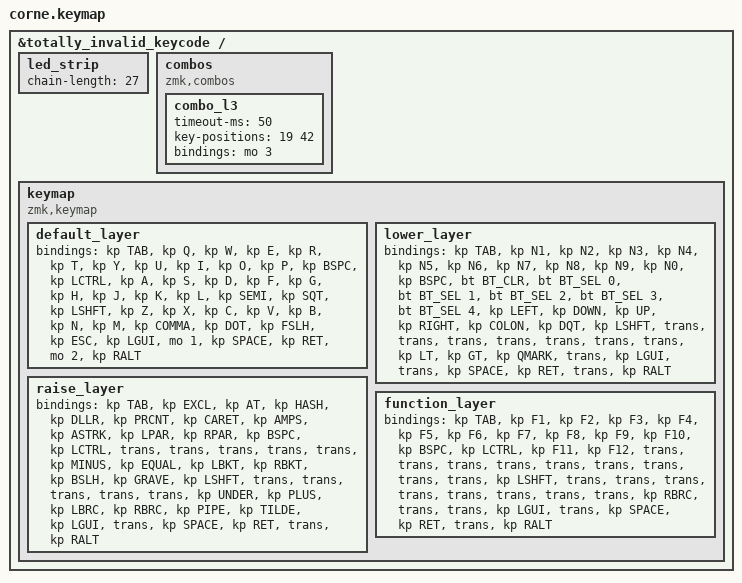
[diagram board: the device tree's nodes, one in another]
/*
 * Copyright (c) 2020 The ZMK Contributors
 *
 * SPDX-License-Identifier: MIT
 */

#include <behaviors.dtsi>
#include <dt-bindings/zmk/keys.h>
#include <dt-bindings/zmk/bt.h>
&totally_invalid_keycode
/ {
        led_strip {
            chain-length = <27>;
        };

        combos {
                compatible = "zmk,combos";
                
                combo_l3 {
                    timeout-ms = <50>;
                    key-positions = <19 42>;
                    bindings = <&mo 3>;
                };
        };

        keymap {
                compatible = "zmk,keymap";

                default_layer {
// -----------------------------------------------------------------------------------------
// |  TAB |  Q  |  W  |  E  |  R  |  T  |   |  Y  |  U   |  I  |  O  |  P  | BSPC |
// | CTRL |  A  |  S  |  D  |  F  |  G  |   |  H  |  J   |  K  |  L  |  ;  |  '   |
// | SHFT |  Z  |  X  |  C  |  V  |  B  |   |  N  |  M   |  ,  |  .  |  /  | ESC  |
//                    | GUI | LWR | SPC |   | ENT | RSE  | ALT |
                        bindings = <
   &kp TAB   &kp Q &kp W &kp E &kp R &kp T   &kp Y &kp U  &kp I     &kp O   &kp P    &kp BSPC
   &kp LCTRL &kp A &kp S &kp D &kp F &kp G   &kp H &kp J  &kp K     &kp L   &kp SEMI &kp SQT
   &kp LSHFT &kp Z &kp X &kp C &kp V &kp B   &kp N &kp M  &kp COMMA &kp DOT &kp FSLH &kp ESC
                  &kp LGUI &mo 1 &kp SPACE   &kp RET &mo 2 &kp RALT
                        >;
                };
                lower_layer {
// -----------------------------------------------------------------------------------------
// |  TAB |  1  |  2  |  3  |  4  |  5  |   |  6  |  7  |  8  |  9  |  0  | BSPC |
// | BTCLR| BT1 | BT2 | BT3 | BT4 | BT5 |   | LFT | DWN |  UP | RGT |  :  |  "   |
// | SHFT |     |     |     |     |     |   |     |     |  <  |  >  |  ?  |      |
//                    | GUI |     | SPC |   | ENT |     | ALT |
                        bindings = <
   &kp TAB    &kp N1       &kp N2       &kp N3       &kp N4       &kp N5         &kp N6   &kp N7   &kp N8 &kp N9    &kp N0 &kp BSPC
   &bt BT_CLR &bt BT_SEL 0 &bt BT_SEL 1 &bt BT_SEL 2 &bt BT_SEL 3 &bt BT_SEL 4   &kp LEFT &kp DOWN &kp UP &kp RIGHT &kp COLON &kp DQT
   &kp LSHFT  &trans       &trans       &trans       &trans       &trans         &trans   &trans   &kp LT &kp GT    &kp QMARK &trans
                                    &kp LGUI     &trans       &kp SPACE      &kp RET  &trans   &kp RALT
                        >;
                };

                raise_layer {
// -----------------------------------------------------------------------------------------
// |  TAB |  !  |  @  |  #  |  $  |  %  |   |  ^  |  &  |  *  |  (  |  )  | BSPC |
// | CTRL |     |     |     |     |     |   |  -  |  =  |  [  |  ]  |  \  |  `   |
// | SHFT |     |     |     |     |     |   |  _  |  +  |  {  |  }  | "|" |  ~   |
//                    | GUI |     | SPC |   | ENT |     | ALT |
                        bindings = <
   &kp  TAB  &kp EXCL &kp AT &kp HASH &kp DLLR &kp PRCNT   &kp CARET &kp AMPS  &kp ASTRK &kp LPAR &kp RPAR &kp BSPC
   &kp LCTRL &trans   &trans &trans   &trans   &trans      &kp MINUS &kp EQUAL &kp LBKT  &kp RBKT &kp BSLH &kp GRAVE
   &kp LSHFT &trans   &trans &trans   &trans   &trans      &kp UNDER &kp PLUS  &kp LBRC  &kp RBRC &kp PIPE &kp TILDE
                             &kp LGUI &trans   &kp SPACE   &kp RET   &trans    &kp RALT
                        >;
                };

                function_layer {
// -----------------------------------------------------------------------------------------
// |  TAB |  F1 |  F2 |  F3 |  F4 |  F5 |   |  F6 |  F7 |  F8 |  F9 | F10 | BSPC |
// | CTRL | F11 | F12 |     |     |     |   |     |     |     |     |     |      |
// | SHFT |     |     |     |     |     |   |     |     |     |     |     |      |
//                    | GUI |     | SPC |   | ENT |     | ALT |
                        bindings = <
   &kp  TAB  &kp F1 &kp F2 &kp F3 &kp F4 &kp F5   &kp F6 &kp F7  &kp F8 &kp F9 &kp F10  &kp BSPC
   &kp LCTRL &kp F11   &kp F12 &trans   &trans   &trans      &trans &trans &trans  &trans &trans &trans
   &kp LSHFT &trans   &trans &trans   &trans   &trans      &trans &trans  &trans  &kp RBRC &trans &trans
                             &kp LGUI &trans   &kp SPACE   &kp RET   &trans    &kp RALT
                        >;
                };
        };
};
